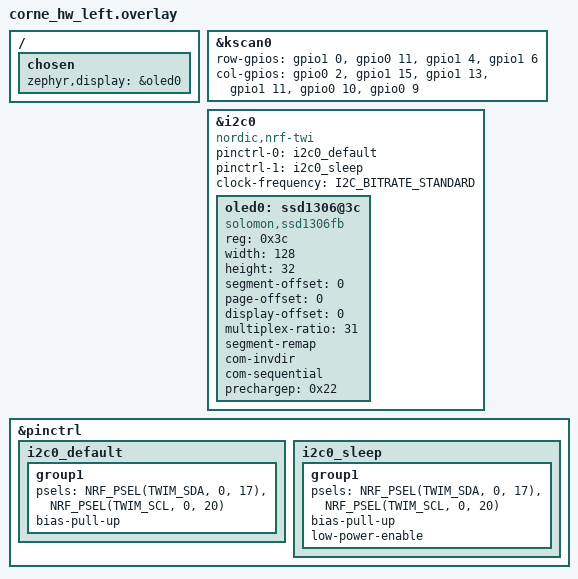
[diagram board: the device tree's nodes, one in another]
/*
 * Copyright (c) 2020 The ZMK Contributors
 *
 * SPDX-License-Identifier: MIT
 */

#include <dt-bindings/pinctrl/nrf-pinctrl.h>
#include <dt-bindings/i2c/i2c.h>
#include "corne_hw.dtsi"

/ {
    chosen {
        zephyr,display = &oled0;
    };
};

&kscan0 {
    row-gpios = <&gpio1 0  (GPIO_ACTIVE_HIGH | GPIO_PULL_DOWN)>,  /* D6 = P1.00 */
                <&gpio0 11 (GPIO_ACTIVE_HIGH | GPIO_PULL_DOWN)>,  /* D7 = P0.11 */
                <&gpio1 4  (GPIO_ACTIVE_HIGH | GPIO_PULL_DOWN)>,  /* D8 = P1.04 */
                <&gpio1 6  (GPIO_ACTIVE_HIGH | GPIO_PULL_DOWN)>;  /* D9 = P1.06 */

    col-gpios = <&gpio0 2  GPIO_ACTIVE_HIGH>,  /* Col 0 = P0.02 */
                <&gpio1 15 GPIO_ACTIVE_HIGH>,  /* Col 1 = P1.15 */
                <&gpio1 13 GPIO_ACTIVE_HIGH>,  /* Col 2 = P1.13 */
                <&gpio1 11 GPIO_ACTIVE_HIGH>,  /* Col 3 = P1.11 */
                <&gpio0 10 GPIO_ACTIVE_HIGH>,  /* Col 4 = P0.10 */
                <&gpio0 9  GPIO_ACTIVE_HIGH>;  /* Col 5 = P0.09 */
};

// OLED configuration - using standard i2c0 on Nice Nano
// Pins: SDA=P0.17, SCL=P0.20 (board defaults)
&i2c0 {
    compatible = "nordic,nrf-twi";
    pinctrl-0 = <&i2c0_default>;
    pinctrl-1 = <&i2c0_sleep>;
    pinctrl-names = "default", "sleep";
    clock-frequency = <I2C_BITRATE_STANDARD>;
    status = "okay";

    oled0: ssd1306@3c {
        compatible = "solomon,ssd1306fb";
        reg = <0x3c>;
        width = <128>;
        height = <32>;
        segment-offset = <0>;
        page-offset = <0>;
        display-offset = <0>;
        multiplex-ratio = <31>;
        segment-remap;
        com-invdir;
        com-sequential;
        prechargep = <0x22>;
    };
};

// Add pinctrl configuration for I2C
&pinctrl {
    i2c0_default: i2c0_default {
        group1 {
            psels = <NRF_PSEL(TWIM_SDA, 0, 17)>,
                    <NRF_PSEL(TWIM_SCL, 0, 20)>;
            bias-pull-up;
        };
    };

    i2c0_sleep: i2c0_sleep {
        group1 {
            psels = <NRF_PSEL(TWIM_SDA, 0, 17)>,
                    <NRF_PSEL(TWIM_SCL, 0, 20)>;
            bias-pull-up;
            low-power-enable;
        };
    };
};

